# STC32G144K246 register map
Vendor: STC; File version: 2.0
Registers are 8-bit, read-write, no defined reset value unless marked. A register's access mark holds for its fields unless they carry their own. Offsets are from the block's base; [hi:lo] are bit positions; {n}, {i} and the like mark numbered series.

## GPIO3 — P3 端口、模式、上下拉和中断
Base 0x007EFD03
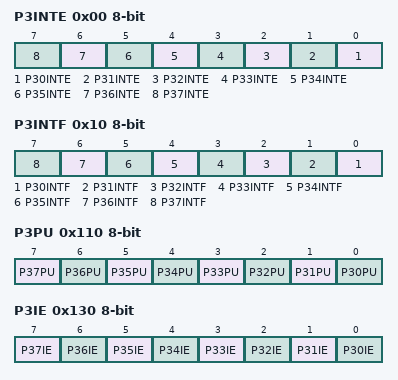
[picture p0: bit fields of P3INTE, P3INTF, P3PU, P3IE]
0x00 P3INTE — P3口中断使能寄存器
  [n-30] P{n}INTE (n=30..37) — 尚未自动匹配到此字段的独立说明；请查看下方章节说明。
0x10 P3INTF ro — P3口中断标志寄存器
  [n-30] P{n}INTF (n=30..37) — 尚未自动匹配到此字段的独立说明；请查看下方章节说明。
0x110 P3PU — P3口上拉电阻控制寄存器
  [all] fields
    0=禁止内部上拉电阻; 1=使能内部上拉电阻
  [7] P37PU — 控制 P3.7 的内部上拉电阻。
  [6] P36PU — 控制 P3.6 的内部上拉电阻。
  [5] P35PU — 控制 P3.5 的内部上拉电阻。
  [4] P34PU — 控制 P3.4 的内部上拉电阻。
  [3] P33PU — 控制 P3.3 的内部上拉电阻。
  [2] P32PU — 控制 P3.2 的内部上拉电阻。
  [1] P31PU — 控制 P3.1 的内部上拉电阻。
  [0] P30PU — 控制 P3.0 的内部上拉电阻。
0x130 P3IE — P3口输入使能控制寄存器
  [all] fields
    0=禁止数字信号输入，用于模拟功能; 1=使能数字信号输入
  [7] P37IE — 控制 P3.7 的数字信号输入。
  [6] P36IE — 控制 P3.6 的数字信号输入。
  [5] P35IE — 控制 P3.5 的数字信号输入。
  [4] P34IE — 控制 P3.4 的数字信号输入。
  [3] P33IE — 控制 P3.3 的数字信号输入。
  [2] P32IE — 控制 P3.2 的数字信号输入。
  [1] P31IE — 控制 P3.1 的数字信号输入。
  [0] P30IE — 控制 P3.0 的数字信号输入。
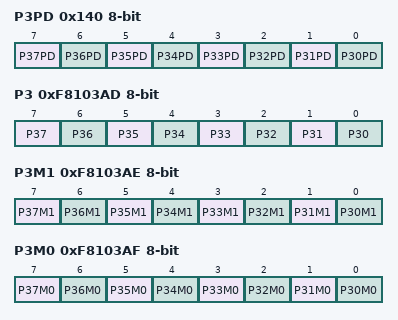
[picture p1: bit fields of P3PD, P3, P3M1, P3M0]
0x140 P3PD — P3口下拉电阻控制寄存器
  [all] fields
    0=禁止内部下拉电阻; 1=使能内部下拉电阻
  [7] P37PD — 控制 P3.7 的内部下拉电阻。
  [6] P36PD — 控制 P3.6 的内部下拉电阻。
  [5] P35PD — 控制 P3.5 的内部下拉电阻。
  [4] P34PD — 控制 P3.4 的内部下拉电阻。
  [3] P33PD — 控制 P3.3 的内部下拉电阻。
  [2] P32PD — 控制 P3.2 的内部下拉电阻。
  [1] P31PD — 控制 P3.1 的内部下拉电阻。
  [0] P30PD — 控制 P3.0 的内部下拉电阻。
0xF8103AD P3 — P3端口
  [all] fields
    0=低电平; 1=高电平
  [7] P37 — 读取 P3.7 管脚电平；写入 P3.7 的输出缓冲区。实际输出行为由端口模式及外设复用共同决定。
  [6] P36 — 读取 P3.6 管脚电平；写入 P3.6 的输出缓冲区。实际输出行为由端口模式及外设复用共同决定。
  [5] P35 — 读取 P3.5 管脚电平；写入 P3.5 的输出缓冲区。实际输出行为由端口模式及外设复用共同决定。
  [4] P34 — 读取 P3.4 管脚电平；写入 P3.4 的输出缓冲区。实际输出行为由端口模式及外设复用共同决定。
  [3] P33 — 读取 P3.3 管脚电平；写入 P3.3 的输出缓冲区。实际输出行为由端口模式及外设复用共同决定。
  [2] P32 — 读取 P3.2 管脚电平；写入 P3.2 的输出缓冲区。实际输出行为由端口模式及外设复用共同决定。
  [1] P31 — 读取 P3.1 管脚电平；写入 P3.1 的输出缓冲区。实际输出行为由端口模式及外设复用共同决定。
  [0] P30 — 读取 P3.0 管脚电平；写入 P3.0 的输出缓冲区。实际输出行为由端口模式及外设复用共同决定。
0xF8103AE P3M1 — P3口配置寄存器1
  [7] P37M1 — 控制 P3.7 的端口模式高位；与 P3M0.B7 配合设置，组合含义见下表。
  [6] P36M1 — 控制 P3.6 的端口模式高位；与 P3M0.B6 配合设置，组合含义见下表。
  [5] P35M1 — 控制 P3.5 的端口模式高位；与 P3M0.B5 配合设置，组合含义见下表。
  [4] P34M1 — 控制 P3.4 的端口模式高位；与 P3M0.B4 配合设置，组合含义见下表。
  [3] P33M1 — 控制 P3.3 的端口模式高位；与 P3M0.B3 配合设置，组合含义见下表。
  [2] P32M1 — 控制 P3.2 的端口模式高位；与 P3M0.B2 配合设置，组合含义见下表。
  [1] P31M1 — 控制 P3.1 的端口模式高位；与 P3M0.B1 配合设置，组合含义见下表。
  [0] P30M1 — 控制 P3.0 的端口模式高位；与 P3M0.B0 配合设置，组合含义见下表。
0xF8103AF P3M0 — P3口配置寄存器0
  [7] P37M0 — 控制 P3.7 的端口模式低位；与 P3M1.B7 配合设置，组合含义见下表。
  [6] P36M0 — 控制 P3.6 的端口模式低位；与 P3M1.B6 配合设置，组合含义见下表。
  [5] P35M0 — 控制 P3.5 的端口模式低位；与 P3M1.B5 配合设置，组合含义见下表。
  [4] P34M0 — 控制 P3.4 的端口模式低位；与 P3M1.B4 配合设置，组合含义见下表。
  [3] P33M0 — 控制 P3.3 的端口模式低位；与 P3M1.B3 配合设置，组合含义见下表。
  [2] P32M0 — 控制 P3.2 的端口模式低位；与 P3M1.B2 配合设置，组合含义见下表。
  [1] P31M0 — 控制 P3.1 的端口模式低位；与 P3M1.B1 配合设置，组合含义见下表。
  [0] P30M0 — 控制 P3.0 的端口模式低位；与 P3M1.B0 配合设置，组合含义见下表。

## GPIO4 — P4 端口、模式、上下拉和中断
Base 0x007EFD04
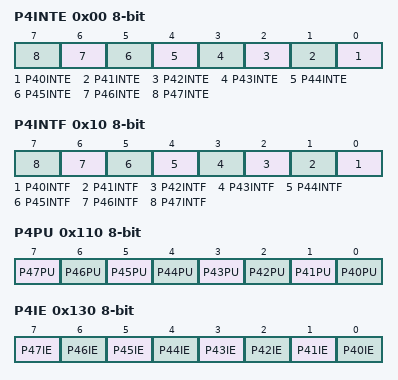
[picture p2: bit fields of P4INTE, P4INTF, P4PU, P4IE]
0x00 P4INTE — P4口中断使能寄存器
  [n-40] P{n}INTE (n=40..47) — 尚未自动匹配到此字段的独立说明；请查看下方章节说明。
0x10 P4INTF ro — P4口中断标志寄存器
  [n-40] P{n}INTF (n=40..47) — 尚未自动匹配到此字段的独立说明；请查看下方章节说明。
0x110 P4PU — P4口上拉电阻控制寄存器
  [all] fields
    0=禁止内部上拉电阻; 1=使能内部上拉电阻
  [7] P47PU — 控制 P4.7 的内部上拉电阻。
  [6] P46PU — 控制 P4.6 的内部上拉电阻。
  [5] P45PU — 控制 P4.5 的内部上拉电阻。
  [4] P44PU — 控制 P4.4 的内部上拉电阻。
  [3] P43PU — 控制 P4.3 的内部上拉电阻。
  [2] P42PU — 控制 P4.2 的内部上拉电阻。
  [1] P41PU — 控制 P4.1 的内部上拉电阻。
  [0] P40PU — 控制 P4.0 的内部上拉电阻。
0x130 P4IE — P4口输入使能控制寄存器
  [all] fields
    0=禁止数字信号输入，用于模拟功能; 1=使能数字信号输入
  [7] P47IE — 控制 P4.7 的数字信号输入。
  [6] P46IE — 控制 P4.6 的数字信号输入。
  [5] P45IE — 控制 P4.5 的数字信号输入。
  [4] P44IE — 控制 P4.4 的数字信号输入。
  [3] P43IE — 控制 P4.3 的数字信号输入。
  [2] P42IE — 控制 P4.2 的数字信号输入。
  [1] P41IE — 控制 P4.1 的数字信号输入。
  [0] P40IE — 控制 P4.0 的数字信号输入。
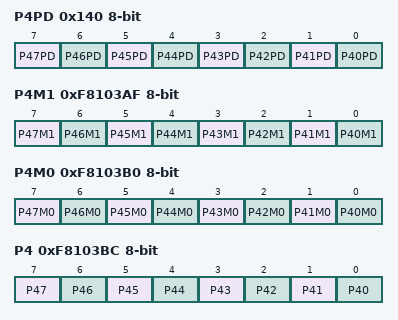
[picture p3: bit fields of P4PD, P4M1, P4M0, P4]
0x140 P4PD — P4口下拉电阻控制寄存器
  [all] fields
    0=禁止内部下拉电阻; 1=使能内部下拉电阻
  [7] P47PD — 控制 P4.7 的内部下拉电阻。
  [6] P46PD — 控制 P4.6 的内部下拉电阻。
  [5] P45PD — 控制 P4.5 的内部下拉电阻。
  [4] P44PD — 控制 P4.4 的内部下拉电阻。
  [3] P43PD — 控制 P4.3 的内部下拉电阻。
  [2] P42PD — 控制 P4.2 的内部下拉电阻。
  [1] P41PD — 控制 P4.1 的内部下拉电阻。
  [0] P40PD — 控制 P4.0 的内部下拉电阻。
0xF8103AF P4M1 — P4口配置寄存器1
  [7] P47M1 — 控制 P4.7 的端口模式高位；与 P4M0.B7 配合设置，组合含义见下表。
  [6] P46M1 — 控制 P4.6 的端口模式高位；与 P4M0.B6 配合设置，组合含义见下表。
  [5] P45M1 — 控制 P4.5 的端口模式高位；与 P4M0.B5 配合设置，组合含义见下表。
  [4] P44M1 — 控制 P4.4 的端口模式高位；与 P4M0.B4 配合设置，组合含义见下表。
  [3] P43M1 — 控制 P4.3 的端口模式高位；与 P4M0.B3 配合设置，组合含义见下表。
  [2] P42M1 — 控制 P4.2 的端口模式高位；与 P4M0.B2 配合设置，组合含义见下表。
  [1] P41M1 — 控制 P4.1 的端口模式高位；与 P4M0.B1 配合设置，组合含义见下表。
  [0] P40M1 — 控制 P4.0 的端口模式高位；与 P4M0.B0 配合设置，组合含义见下表。
0xF8103B0 P4M0 — P4口配置寄存器0
  [7] P47M0 — 控制 P4.7 的端口模式低位；与 P4M1.B7 配合设置，组合含义见下表。
  [6] P46M0 — 控制 P4.6 的端口模式低位；与 P4M1.B6 配合设置，组合含义见下表。
  [5] P45M0 — 控制 P4.5 的端口模式低位；与 P4M1.B5 配合设置，组合含义见下表。
  [4] P44M0 — 控制 P4.4 的端口模式低位；与 P4M1.B4 配合设置，组合含义见下表。
  [3] P43M0 — 控制 P4.3 的端口模式低位；与 P4M1.B3 配合设置，组合含义见下表。
  [2] P42M0 — 控制 P4.2 的端口模式低位；与 P4M1.B2 配合设置，组合含义见下表。
  [1] P41M0 — 控制 P4.1 的端口模式低位；与 P4M1.B1 配合设置，组合含义见下表。
  [0] P40M0 — 控制 P4.0 的端口模式低位；与 P4M1.B0 配合设置，组合含义见下表。
0xF8103BC P4 — P4端口
  [all] fields
    0=低电平; 1=高电平
  [7] P47 — 读取 P4.7 管脚电平；写入 P4.7 的输出缓冲区。实际输出行为由端口模式及外设复用共同决定。
  [6] P46 — 读取 P4.6 管脚电平；写入 P4.6 的输出缓冲区。实际输出行为由端口模式及外设复用共同决定。
  [5] P45 — 读取 P4.5 管脚电平；写入 P4.5 的输出缓冲区。实际输出行为由端口模式及外设复用共同决定。
  [4] P44 — 读取 P4.4 管脚电平；写入 P4.4 的输出缓冲区。实际输出行为由端口模式及外设复用共同决定。
  [3] P43 — 读取 P4.3 管脚电平；写入 P4.3 的输出缓冲区。实际输出行为由端口模式及外设复用共同决定。
  [2] P42 — 读取 P4.2 管脚电平；写入 P4.2 的输出缓冲区。实际输出行为由端口模式及外设复用共同决定。
  [1] P41 — 读取 P4.1 管脚电平；写入 P4.1 的输出缓冲区。实际输出行为由端口模式及外设复用共同决定。
  [0] P40 — 读取 P4.0 管脚电平；写入 P4.0 的输出缓冲区。实际输出行为由端口模式及外设复用共同决定。
